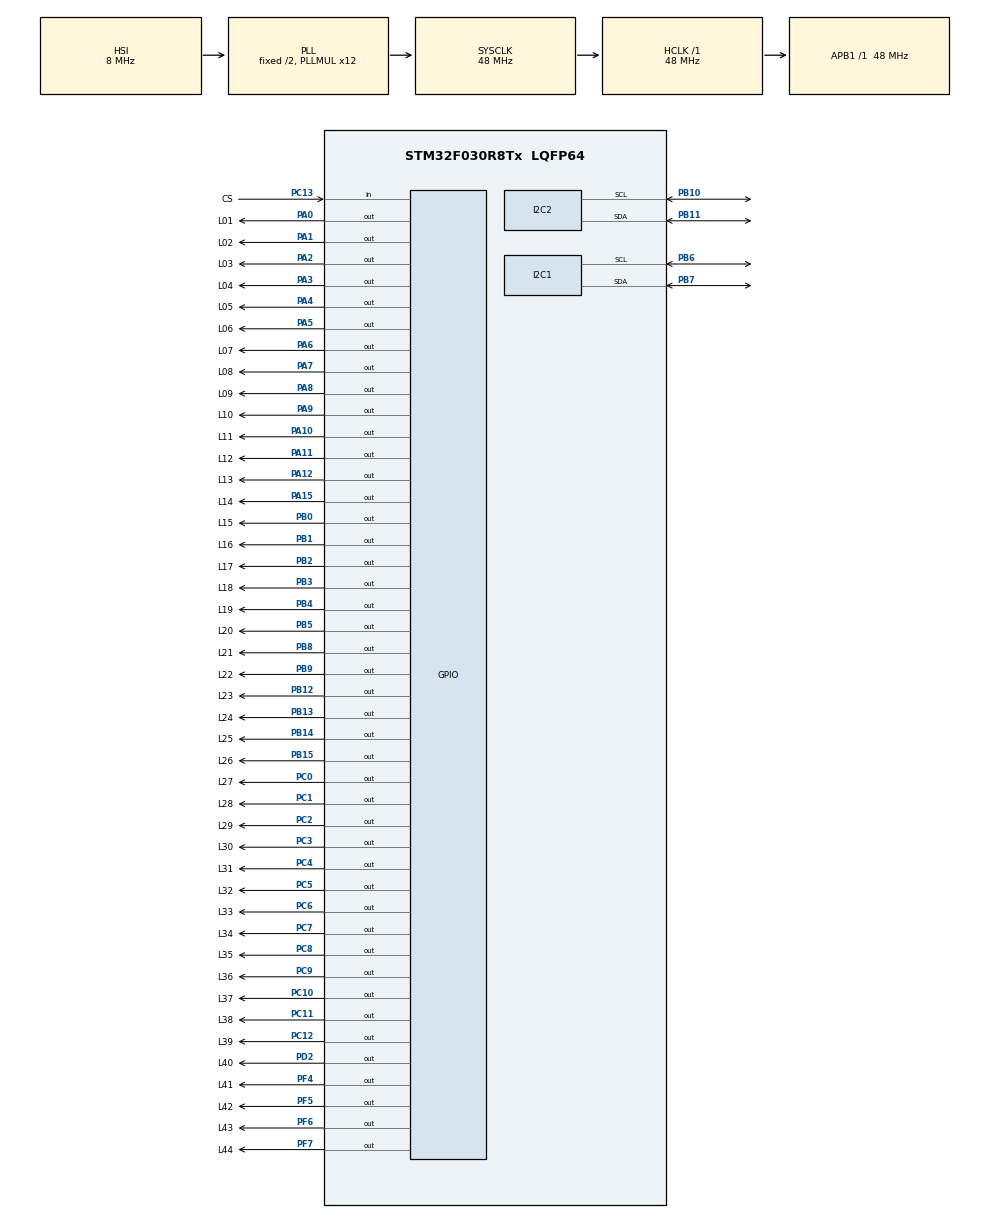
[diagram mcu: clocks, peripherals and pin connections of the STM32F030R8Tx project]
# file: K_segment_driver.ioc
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Dma.I2C1_RX.0.Direction=DMA_PERIPH_TO_MEMORY
Dma.I2C1_RX.0.Instance=DMA1_Channel3
Dma.I2C1_RX.0.MemDataAlignment=DMA_MDATAALIGN_BYTE
Dma.I2C1_RX.0.MemInc=DMA_MINC_ENABLE
Dma.I2C1_RX.0.Mode=DMA_CIRCULAR
Dma.I2C1_RX.0.PeriphDataAlignment=DMA_PDATAALIGN_BYTE
Dma.I2C1_RX.0.PeriphInc=DMA_PINC_DISABLE
Dma.I2C1_RX.0.Priority=DMA_PRIORITY_LOW
Dma.Request0=I2C1_RX
I2C1.Timing=0x20303E5D
I2C2.Timing=0x20303E5D
Mcu.Family=STM32F0
Mcu.Name=STM32F030R8Tx
Mcu.Package=LQFP64
NVIC.DMA1_Channel2_3_IRQn=true\:0\:0\:false\:false\:true\:false\:true\:true
PA0.GPIO_Label=L01
PA0.GPIO_Speed=GPIO_SPEED_FREQ_MEDIUM
PA0.Signal=GPIO_Output
PA1.GPIO_Label=L02
PA1.GPIO_Speed=GPIO_SPEED_FREQ_MEDIUM
PA1.Signal=GPIO_Output
PA10.GPIO_Label=L11
PA10.GPIO_Speed=GPIO_SPEED_FREQ_MEDIUM
PA10.Signal=GPIO_Output
PA11.GPIO_Label=L12
PA11.GPIO_Speed=GPIO_SPEED_FREQ_MEDIUM
PA11.Signal=GPIO_Output
PA12.GPIO_Label=L13
PA12.GPIO_Speed=GPIO_SPEED_FREQ_MEDIUM
PA12.Signal=GPIO_Output
PA13.Mode=Serial_Wire
PA13.Signal=SYS_SWDIO
PA14.Mode=Serial_Wire
PA14.Signal=SYS_SWCLK
PA15.GPIO_Label=L14
PA15.GPIO_Speed=GPIO_SPEED_FREQ_MEDIUM
PA15.Signal=GPIO_Output
PA2.GPIO_Label=L03
PA2.GPIO_Speed=GPIO_SPEED_FREQ_MEDIUM
PA2.Signal=GPIO_Output
PA3.GPIO_Label=L04
PA3.GPIO_Speed=GPIO_SPEED_FREQ_MEDIUM
PA3.Signal=GPIO_Output
PA4.GPIO_Label=L05
PA4.GPIO_Speed=GPIO_SPEED_FREQ_MEDIUM
PA4.Signal=GPIO_Output
PA5.GPIO_Label=L06
PA5.GPIO_Speed=GPIO_SPEED_FREQ_MEDIUM
PA5.Signal=GPIO_Output
PA6.GPIO_Label=L07
PA6.GPIO_Speed=GPIO_SPEED_FREQ_MEDIUM
PA6.Signal=GPIO_Output
PA7.GPIO_Label=L08
PA7.GPIO_Speed=GPIO_SPEED_FREQ_MEDIUM
PA7.Signal=GPIO_Output
PA8.GPIO_Label=L09
PA8.GPIO_Speed=GPIO_SPEED_FREQ_MEDIUM
PA8.Signal=GPIO_Output
PA9.GPIO_Label=L10
PA9.GPIO_Speed=GPIO_SPEED_FREQ_MEDIUM
PA9.Signal=GPIO_Output
PB0.GPIO_Label=L15
PB0.GPIO_Speed=GPIO_SPEED_FREQ_MEDIUM
PB0.Signal=GPIO_Output
PB1.GPIO_Label=L16
PB1.GPIO_Speed=GPIO_SPEED_FREQ_MEDIUM
PB1.Signal=GPIO_Output
PB10.Mode=I2C
PB10.Signal=I2C2_SCL
PB11.Mode=I2C
PB11.Signal=I2C2_SDA
PB12.GPIO_Label=L23
PB12.GPIO_Speed=GPIO_SPEED_FREQ_MEDIUM
PB12.Signal=GPIO_Output
PB13.GPIO_Label=L24
PB13.GPIO_Speed=GPIO_SPEED_FREQ_MEDIUM
PB13.Signal=GPIO_Output
PB14.GPIO_Label=L25
PB14.GPIO_Speed=GPIO_SPEED_FREQ_MEDIUM
PB14.Signal=GPIO_Output
PB15.GPIO_Label=L26
PB15.GPIO_Speed=GPIO_SPEED_FREQ_MEDIUM
PB15.Signal=GPIO_Output
PB2.GPIO_Label=L17
PB2.GPIO_Speed=GPIO_SPEED_FREQ_MEDIUM
PB2.Signal=GPIO_Output
PB3.GPIO_Label=L18
PB3.GPIO_Speed=GPIO_SPEED_FREQ_MEDIUM
PB3.Signal=GPIO_Output
PB4.GPIO_Label=L19
PB4.GPIO_Speed=GPIO_SPEED_FREQ_MEDIUM
PB4.Signal=GPIO_Output
PB5.GPIO_Label=L20
PB5.GPIO_Speed=GPIO_SPEED_FREQ_MEDIUM
PB5.Signal=GPIO_Output
PB6.Mode=I2C
PB6.Signal=I2C1_SCL
PB7.Mode=I2C
PB7.Signal=I2C1_SDA
PB8.GPIO_Label=L21
PB8.GPIO_Speed=GPIO_SPEED_FREQ_MEDIUM
PB8.Signal=GPIO_Output
PB9.GPIO_Label=L22
PB9.GPIO_Speed=GPIO_SPEED_FREQ_MEDIUM
PB9.Signal=GPIO_Output
PC0.GPIO_Label=L27
PC0.GPIO_Speed=GPIO_SPEED_FREQ_MEDIUM
PC0.Signal=GPIO_Output
PC1.GPIO_Label=L28
PC1.GPIO_Speed=GPIO_SPEED_FREQ_MEDIUM
PC1.Signal=GPIO_Output
PC10.GPIO_Label=L37
PC10.GPIO_Speed=GPIO_SPEED_FREQ_MEDIUM
PC10.Signal=GPIO_Output
PC11.GPIO_Label=L38
PC11.GPIO_Speed=GPIO_SPEED_FREQ_MEDIUM
PC11.Signal=GPIO_Output
PC12.GPIO_Label=L39
PC12.GPIO_Speed=GPIO_SPEED_FREQ_MEDIUM
PC12.Signal=GPIO_Output
PC13.GPIO_Label=CS
PC13.Signal=GPIO_Input
PC2.GPIO_Label=L29
PC2.GPIO_Speed=GPIO_SPEED_FREQ_MEDIUM
PC2.Signal=GPIO_Output
PC3.GPIO_Label=L30
PC3.GPIO_Speed=GPIO_SPEED_FREQ_MEDIUM
PC3.Signal=GPIO_Output
PC4.GPIO_Label=L31
PC4.GPIO_Speed=GPIO_SPEED_FREQ_MEDIUM
PC4.Signal=GPIO_Output
PC5.GPIO_Label=L32
PC5.GPIO_Speed=GPIO_SPEED_FREQ_MEDIUM
PC5.Signal=GPIO_Output
PC6.GPIO_Label=L33
PC6.GPIO_Speed=GPIO_SPEED_FREQ_MEDIUM
PC6.Signal=GPIO_Output
PC7.GPIO_Label=L34
PC7.GPIO_Speed=GPIO_SPEED_FREQ_MEDIUM
PC7.Signal=GPIO_Output
PC8.GPIO_Label=L35
PC8.GPIO_Speed=GPIO_SPEED_FREQ_MEDIUM
PC8.Signal=GPIO_Output
PC9.GPIO_Label=L36
PC9.GPIO_Speed=GPIO_SPEED_FREQ_MEDIUM
PC9.Signal=GPIO_Output
PD2.GPIO_Label=L40
PD2.GPIO_Speed=GPIO_SPEED_FREQ_MEDIUM
PD2.Signal=GPIO_Output
PF4.GPIO_Label=L41
PF4.GPIO_Speed=GPIO_SPEED_FREQ_MEDIUM
PF4.Signal=GPIO_Output
PF5.GPIO_Label=L42
PF5.GPIO_Speed=GPIO_SPEED_FREQ_MEDIUM
PF5.Signal=GPIO_Output
PF6.GPIO_Label=L43
PF6.GPIO_Speed=GPIO_SPEED_FREQ_MEDIUM
PF6.Signal=GPIO_Output
PF7.GPIO_Label=L44
PF7.GPIO_Speed=GPIO_SPEED_FREQ_MEDIUM
PF7.Signal=GPIO_Output
ProjectManager.HeapSize=0x200
ProjectManager.StackSize=0x400
ProjectManager.TargetToolchain=EWARM V8.32
RCC.AHBFreq_Value=48000000
RCC.APB1Freq_Value=48000000
RCC.APB1TimFreq_Value=48000000
RCC.HCLKFreq_Value=48000000
RCC.I2c1ClockSelection=RCC_I2C1CLKSOURCE_SYSCLK
RCC.PLLMUL=RCC_PLL_MUL12
RCC.SYSCLKFreq_VALUE=48000000
RCC.SYSCLKSource=RCC_SYSCLKSOURCE_PLLCLK
board=custom

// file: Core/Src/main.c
/* USER CODE BEGIN Header */
/**
  ******************************************************************************
  * @file           : main.c
  * @brief          : Main program body
  ******************************************************************************
  * @attention
  *
  * Copyright (c) 2023 STMicroelectronics.
  * All rights reserved.
  *
  * This software is licensed under terms that can be found in the LICENSE file
  * in the root directory of this software component.
  * If no LICENSE file comes with this software, it is provided AS-IS.
  *
  ******************************************************************************
  */
/* USER CODE END Header */
#include "main.h"

/* USER CODE BEGIN Includes */
#include "../../Main/Inc/user_main.h"
/* USER CODE END Includes */

I2C_HandleTypeDef hi2c1;
I2C_HandleTypeDef hi2c2;
DMA_HandleTypeDef hdma_i2c1_rx;

void SystemClock_Config(void);
static void MX_GPIO_Init(void);
static void MX_DMA_Init(void);
static void MX_I2C1_Init(void);
static void MX_I2C2_Init(void);

int main(void)
{

  /* MCU Configuration--------------------------------------------------------*/

  /* Reset of all peripherals, Initializes the Flash interface and the Systick. */
  HAL_Init();

  /* Configure the system clock */
  SystemClock_Config();

  /* Initialize all configured peripherals */
  MX_GPIO_Init();
  MX_DMA_Init();
  MX_I2C1_Init();
  MX_I2C2_Init();
  /* USER CODE BEGIN 2 */
  initTask();
  /* USER CODE END 2 */

  /* Infinite loop */
  while (1)
  {

    /* USER CODE BEGIN 3 */
    mainTask();
  }
  /* USER CODE END 3 */
}

void SystemClock_Config(void)
{
  RCC_OscInitTypeDef RCC_OscInitStruct = {0};
  RCC_ClkInitTypeDef RCC_ClkInitStruct = {0};
  RCC_PeriphCLKInitTypeDef PeriphClkInit = {0};

  /** Initializes the RCC Oscillators according to the specified parameters
  * in the RCC_OscInitTypeDef structure.
  */
  RCC_OscInitStruct.OscillatorType = RCC_OSCILLATORTYPE_HSI;
  RCC_OscInitStruct.HSIState = RCC_HSI_ON;
  RCC_OscInitStruct.HSICalibrationValue = RCC_HSICALIBRATION_DEFAULT;
  RCC_OscInitStruct.PLL.PLLState = RCC_PLL_ON;
  RCC_OscInitStruct.PLL.PLLSource = RCC_PLLSOURCE_HSI;
  RCC_OscInitStruct.PLL.PLLMUL = RCC_PLL_MUL12;
  RCC_OscInitStruct.PLL.PREDIV = RCC_PREDIV_DIV1;
  if (HAL_RCC_OscConfig(&RCC_OscInitStruct) != HAL_OK)
  {
    Error_Handler();
  }

  /** Initializes the CPU, AHB and APB buses clocks
  */
  RCC_ClkInitStruct.ClockType = RCC_CLOCKTYPE_HCLK|RCC_CLOCKTYPE_SYSCLK
                              |RCC_CLOCKTYPE_PCLK1;
  RCC_ClkInitStruct.SYSCLKSource = RCC_SYSCLKSOURCE_PLLCLK;
  RCC_ClkInitStruct.AHBCLKDivider = RCC_SYSCLK_DIV1;
  RCC_ClkInitStruct.APB1CLKDivider = RCC_HCLK_DIV1;

  if (HAL_RCC_ClockConfig(&RCC_ClkInitStruct, FLASH_LATENCY_1) != HAL_OK)
  {
    Error_Handler();
  }
  PeriphClkInit.PeriphClockSelection = RCC_PERIPHCLK_I2C1;
  PeriphClkInit.I2c1ClockSelection = RCC_I2C1CLKSOURCE_SYSCLK;
  if (HAL_RCCEx_PeriphCLKConfig(&PeriphClkInit) != HAL_OK)
  {
    Error_Handler();
  }
}

static void MX_I2C1_Init(void)
{

  hi2c1.Instance = I2C1;
  hi2c1.Init.Timing = 0x20303E5D;
  hi2c1.Init.OwnAddress1 = 0;
  hi2c1.Init.AddressingMode = I2C_ADDRESSINGMODE_7BIT;
  hi2c1.Init.DualAddressMode = I2C_DUALADDRESS_DISABLE;
  hi2c1.Init.OwnAddress2 = 0;
  hi2c1.Init.OwnAddress2Masks = I2C_OA2_NOMASK;
  hi2c1.Init.GeneralCallMode = I2C_GENERALCALL_DISABLE;
  hi2c1.Init.NoStretchMode = I2C_NOSTRETCH_DISABLE;
  if (HAL_I2C_Init(&hi2c1) != HAL_OK)
  {
    Error_Handler();
  }

  /** Configure Analogue filter
  */
  if (HAL_I2CEx_ConfigAnalogFilter(&hi2c1, I2C_ANALOGFILTER_ENABLE) != HAL_OK)
  {
    Error_Handler();
  }

  /** Configure Digital filter
  */
  if (HAL_I2CEx_ConfigDigitalFilter(&hi2c1, 0) != HAL_OK)
  {
    Error_Handler();
  }

}

static void MX_I2C2_Init(void)
{

  hi2c2.Instance = I2C2;
  hi2c2.Init.Timing = 0x20303E5D;
  hi2c2.Init.OwnAddress1 = 0;
  hi2c2.Init.AddressingMode = I2C_ADDRESSINGMODE_7BIT;
  hi2c2.Init.DualAddressMode = I2C_DUALADDRESS_DISABLE;
  hi2c2.Init.OwnAddress2 = 0;
  hi2c2.Init.OwnAddress2Masks = I2C_OA2_NOMASK;
  hi2c2.Init.GeneralCallMode = I2C_GENERALCALL_DISABLE;
  hi2c2.Init.NoStretchMode = I2C_NOSTRETCH_DISABLE;
  if (HAL_I2C_Init(&hi2c2) != HAL_OK)
  {
    Error_Handler();
  }

  /** Configure Analogue filter
  */
  if (HAL_I2CEx_ConfigAnalogFilter(&hi2c2, I2C_ANALOGFILTER_ENABLE) != HAL_OK)
  {
    Error_Handler();
  }

  /** Configure Digital filter
  */
  if (HAL_I2CEx_ConfigDigitalFilter(&hi2c2, 0) != HAL_OK)
  {
    Error_Handler();
  }

}

static void MX_DMA_Init(void)
{

  /* DMA controller clock enable */
  __HAL_RCC_DMA1_CLK_ENABLE();

  /* DMA interrupt init */
  /* DMA1_Channel2_3_IRQn interrupt configuration */
  HAL_NVIC_SetPriority(DMA1_Channel2_3_IRQn, 0, 0);
  HAL_NVIC_EnableIRQ(DMA1_Channel2_3_IRQn);

}

static void MX_GPIO_Init(void)
{
  GPIO_InitTypeDef GPIO_InitStruct = {0};

  /* GPIO Ports Clock Enable */
  __HAL_RCC_GPIOC_CLK_ENABLE();
  __HAL_RCC_GPIOA_CLK_ENABLE();
  __HAL_RCC_GPIOF_CLK_ENABLE();
  __HAL_RCC_GPIOB_CLK_ENABLE();
  __HAL_RCC_GPIOD_CLK_ENABLE();

  /*Configure GPIO pin Output Level */
  HAL_GPIO_WritePin(GPIOC, L27_Pin|L28_Pin|L29_Pin|L30_Pin
                          |L31_Pin|L32_Pin|L33_Pin|L34_Pin
                          |L35_Pin|L36_Pin|L37_Pin|L38_Pin
                          |L39_Pin, GPIO_PIN_RESET);

  /*Configure GPIO pin Output Level */
  HAL_GPIO_WritePin(GPIOA, L01_Pin|L02_Pin|L03_Pin|L04_Pin
                          |L05_Pin|L06_Pin|L07_Pin|L08_Pin
                          |L09_Pin|L10_Pin|L11_Pin|L12_Pin
                          |L13_Pin|L14_Pin, GPIO_PIN_RESET);

  /*Configure GPIO pin Output Level */
  HAL_GPIO_WritePin(GPIOF, L41_Pin|L42_Pin|L43_Pin|L44_Pin, GPIO_PIN_RESET);

  /*Configure GPIO pin Output Level */
  HAL_GPIO_WritePin(GPIOB, L15_Pin|L16_Pin|L17_Pin|L23_Pin
                          |L24_Pin|L25_Pin|L26_Pin|L18_Pin
                          |L19_Pin|L20_Pin|L21_Pin|L22_Pin, GPIO_PIN_RESET);

  /*Configure GPIO pin Output Level */
  HAL_GPIO_WritePin(L40_GPIO_Port, L40_Pin, GPIO_PIN_RESET);

  /*Configure GPIO pin : CS_Pin */
  GPIO_InitStruct.Pin = CS_Pin;
  GPIO_InitStruct.Mode = GPIO_MODE_INPUT;
  GPIO_InitStruct.Pull = GPIO_NOPULL;
  HAL_GPIO_Init(CS_GPIO_Port, &GPIO_InitStruct);

  /*Configure GPIO pins : L27_Pin L28_Pin L29_Pin L30_Pin
                           L31_Pin L32_Pin L33_Pin L34_Pin
                           L35_Pin L36_Pin L37_Pin L38_Pin
                           L39_Pin */
  GPIO_InitStruct.Pin = L27_Pin|L28_Pin|L29_Pin|L30_Pin
                          |L31_Pin|L32_Pin|L33_Pin|L34_Pin
                          |L35_Pin|L36_Pin|L37_Pin|L38_Pin
                          |L39_Pin;
  GPIO_InitStruct.Mode = GPIO_MODE_OUTPUT_PP;
  GPIO_InitStruct.Pull = GPIO_NOPULL;
  GPIO_InitStruct.Speed = GPIO_SPEED_FREQ_MEDIUM;
  HAL_GPIO_Init(GPIOC, &GPIO_InitStruct);

  /*Configure GPIO pins : L01_Pin L02_Pin L03_Pin L04_Pin
                           L05_Pin L06_Pin L07_Pin L08_Pin
                           L09_Pin L10_Pin L11_Pin L12_Pin
                           L13_Pin L14_Pin */
  GPIO_InitStruct.Pin = L01_Pin|L02_Pin|L03_Pin|L04_Pin
                          |L05_Pin|L06_Pin|L07_Pin|L08_Pin
                          |L09_Pin|L10_Pin|L11_Pin|L12_Pin
                          |L13_Pin|L14_Pin;
  GPIO_InitStruct.Mode = GPIO_MODE_OUTPUT_PP;
  GPIO_InitStruct.Pull = GPIO_NOPULL;
  GPIO_InitStruct.Speed = GPIO_SPEED_FREQ_MEDIUM;
  HAL_GPIO_Init(GPIOA, &GPIO_InitStruct);

  /*Configure GPIO pins : L41_Pin L42_Pin L43_Pin L44_Pin */
  GPIO_InitStruct.Pin = L41_Pin|L42_Pin|L43_Pin|L44_Pin;
  GPIO_InitStruct.Mode = GPIO_MODE_OUTPUT_PP;
  GPIO_InitStruct.Pull = GPIO_NOPULL;
  GPIO_InitStruct.Speed = GPIO_SPEED_FREQ_MEDIUM;
  HAL_GPIO_Init(GPIOF, &GPIO_InitStruct);

  /*Configure GPIO pins : L15_Pin L16_Pin L17_Pin L23_Pin
                           L24_Pin L25_Pin L26_Pin L18_Pin
                           L19_Pin L20_Pin L21_Pin L22_Pin */
  GPIO_InitStruct.Pin = L15_Pin|L16_Pin|L17_Pin|L23_Pin
                          |L24_Pin|L25_Pin|L26_Pin|L18_Pin
                          |L19_Pin|L20_Pin|L21_Pin|L22_Pin;
  GPIO_InitStruct.Mode = GPIO_MODE_OUTPUT_PP;
  GPIO_InitStruct.Pull = GPIO_NOPULL;
  GPIO_InitStruct.Speed = GPIO_SPEED_FREQ_MEDIUM;
  HAL_GPIO_Init(GPIOB, &GPIO_InitStruct);

  /*Configure GPIO pin : L40_Pin */
  GPIO_InitStruct.Pin = L40_Pin;
  GPIO_InitStruct.Mode = GPIO_MODE_OUTPUT_PP;
  GPIO_InitStruct.Pull = GPIO_NOPULL;
  GPIO_InitStruct.Speed = GPIO_SPEED_FREQ_MEDIUM;
  HAL_GPIO_Init(L40_GPIO_Port, &GPIO_InitStruct);

}

void Error_Handler(void)
{
  __disable_irq();
  while (1)
  {
  }
}
